# M4KQ register map
File version: 0.1
TOSHIBA Cortex-M4 MCU
Registers are 32-bit, read-write, reset 0x0 unless marked. A register's access mark holds for its fields unless they carry their own. Offsets are from the block's base; lines under a group give offsets from that group; [hi:lo] are bit positions; {n}, {i} and the like mark numbered series; 'fields as' and 'values as' point back to an identical list; <NAME> marks a mode.

## Memory map
0x40005000 CANMB0 blocks up to offset 0x1C — CAN Controller Mailbox RAM (CANMB)
{0x40005000+0x20*n} CANMB{n} blocks up to offset 0x1C (n=1..31)
0x40005400 CAN blocks up to offset 0xBC — CAN Controller (CAN)
0x4003E000 IA size 0x1 — Interrupt control A Register (IA)
0x4003E400 RLM blocks up to offset 0x4 — Reset Low power Managiment Register (RLM)
0x4003EC00 LVD size 0x1 — Voltage detection circuit (LVD)
0x40043000 RPAR0 size 0x14 — RAM Parity (RAMP)
0x40043100 CRC blocks up to offset 0x30 — CRC Calculation Circuit (CRC)
0x40083000 CG blocks up to offset 0x60 — Clock Control and Operation Mode (CG)
0x40083200 IB blocks up to offset 0xA6 — Interrupt Control B Register (IB)
0x40083300 IMN blocks up to offset 0x18 — Interrupt Monitor Register (IMN)
0x400A0200 DNFA size 0x8 — Digital Noise Filter (DNF)
0x400A0300 DNFB size 0x8
0x400A0400 TSEL size 0x2C — Trigger Selection circuit (TSEL)
0x400A0600 SIWD size 0x18 — Watchdog Timer (SIWD)
0x400A0800 DNFC size 0x8
0x400A2000 NBD size 0x8 — Non-Break Debug Interface (NBD)
0x400A3000 RPAR1 size 0x14
0x400A4000 DMA blocks up to offset 0x50 — Direct Memory Accsess Controller (DMAC)
0x400BA000 ADA blocks up to offset 0x1A0 — 12-bit Analog to Digital Converter(ADC)
0x400BA400 ADB blocks up to offset 0x1A0
0x400BA800 ADC blocks up to offset 0x1A0
0x400BD000 AMP size 0xC — Gain Op-AMP (AMP)
0x400C1000 T32A0 blocks up to offset 0xFC — 32-bit Timer Event Counter (T32A)
0x400C1400 T32A1 blocks up to offset 0xFC
0x400C1800 T32A2 blocks up to offset 0xFC
0x400C1C00 T32A3 blocks up to offset 0xFC
0x400C2000 T32A4 blocks up to offset 0xFC
0x400C2400 T32A5 blocks up to offset 0xFC
0x400CA000 TSPI0 blocks up to offset 0x208 — Serial Peripheral Interface (TSPI)
0x400CA400 TSPI1 blocks up to offset 0x208
0x400CE000 UART0 size 0x28 — Asynchronous Serial Communication Circuit (UART)
0x400CE400 UART1 size 0x28
0x400CE800 UART2 size 0x28
0x400CEC00 UART3 size 0x28
0x400D1000 I2C0 size 0x28 — I2C Interface (I2C)
0x400D2000 I2C1 size 0x28
0x400E0000 PA blocks up to offset 0x3C — Port A
0x400E0100 PB blocks up to offset 0x3C — Port B
0x400E0200 PC blocks up to offset 0x3C — Port C
0x400E0300 PD blocks up to offset 0x3C — Port D
0x400E0400 PE blocks up to offset 0x3C — Port E
0x400E0500 PF blocks up to offset 0x3C — Port F
0x400E0600 PG blocks up to offset 0x3C — Port G
0x400E0700 PH blocks up to offset 0x3C — Port H
0x400E0800 PJ blocks up to offset 0x3C — Port J
0x400E0900 PK blocks up to offset 0x3C — Port K
0x400E0A00 PL blocks up to offset 0x3C — Port L
0x400E0B00 PM blocks up to offset 0x3C — Port M
0x400E0C00 PN blocks up to offset 0x3C — Port N
0x400E0D00 PP blocks up to offset 0x3C — Port P
0x400E0E00 PR blocks up to offset 0x3C — Port R
0x400E0F00 PT blocks up to offset 0x3C — Port T
0x400E1000 PU blocks up to offset 0x3C — Port U
0x400E1100 PV blocks up to offset 0x3C — Port V
0x400E1200 PW blocks up to offset 0x3C — Port W
0x400E3100 TRM size 0x10 — Trimming Circuit (TRM)
0x400E4000 OFD size 0x24 — Oscillation Frequency Detector (OFD)
0x400E9000 PMD0 size 0x7C — Advanced Progammable Motor Control Circuit (A-PMD)
0x400E9400 PMD1 size 0x7C
0x400E9800 PMD2 size 0x7C
0x400EA000 EN0 size 0x34 — Advanced Encoder Input (A-ENC32)
0x400EA400 EN1 size 0x34
0x400EA800 EN2 size 0x34
0x400EB000 VE blocks up to offset 0x248 — Advanced Vector Engine Plus (A-VE+)
0x5DFF0000 FC blocks up to offset 0x15C — Flash Memory Interface (FC)

## CANMB0 — CAN Controller Mailbox RAM (CANMB)
Base 0x40005000
Same registers: CANMB{n} {0x40005000+0x20*n} (n=1..31)
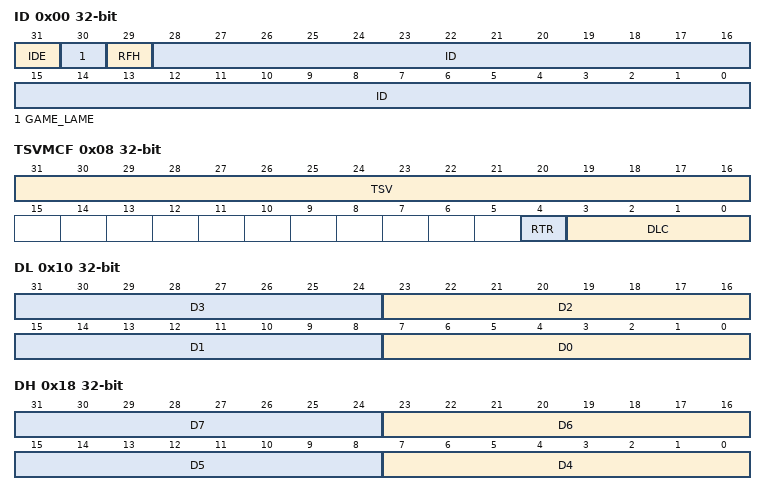
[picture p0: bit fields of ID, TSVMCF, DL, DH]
0x00 ID reset not defined — CAN Mailbox ID
  [31] IDE, [30] GAME_LAME, [29] RFH, [28:0] ID
0x08 TSVMCF reset not defined — CAN Mailbox Time Stamp Value and Message Control Field
  [31:16] TSV, [4] RTR, [3:0] DLC
0x10 DL reset not defined — CAN Mailbox Lower Data Field (D3-D0)
  [8n+7:8n] D{n} (n=0..3)
0x18 DH reset not defined — CAN Mailbox Upper Data Field (D7-D4)
  [8n-25:8n-32] D{n} (n=4..7)
